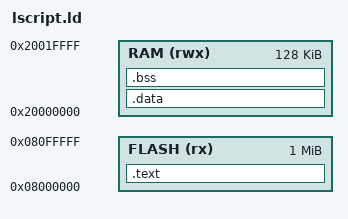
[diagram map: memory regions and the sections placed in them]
MEMORY
{
  FLASH (rx)  : ORIGIN = 0x08000000, LENGTH = 1M
  RAM   (rwx) : ORIGIN = 0x20000000, LENGTH = 128K
}

__stack_start = ORIGIN(RAM) + LENGTH(RAM);

SECTIONS
{
  .text : {
    KEEP(*(.isr_vector))
    *(.text*)
    *(.rodata*)
  } > FLASH

  .data : { *(.data*) } > RAM
  .bss  : { *(.bss*) *(COMMON) } > RAM
}
